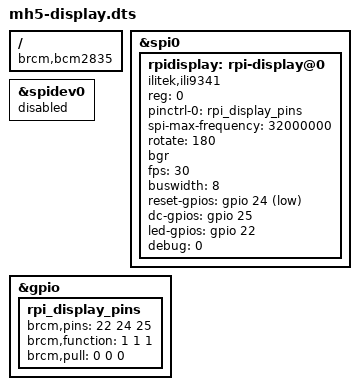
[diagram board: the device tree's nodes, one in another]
/*
 * Device Tree overlay for MH5 Display
 * based on rpi-display by Watterott
 *
 */

/dts-v1/;
/plugin/;

/ {
	compatible = "brcm,bcm2835";

	fragment@0 {
		target = <&spi0>;
		__overlay__ {
			status = "okay";
		};
	};

	fragment@1 {
		target = <&spidev0>;
		__overlay__ {
			status = "disabled";
		};
	};

	fragment@3 {
		target = <&gpio>;
		__overlay__ {
			rpi_display_pins: rpi_display_pins {
				brcm,pins = <22 24 25>;
				brcm,function = <1 1 1>; /* out out out out */
				brcm,pull = <0 0 0>; /* - - - - */
			};
		};
	};

	fragment@4 {
		target = <&spi0>;
		__overlay__ {
			/* needed to avoid dtc warning */
			#address-cells = <1>;
			#size-cells = <0>;

			rpidisplay: rpi-display@0{
				compatible = "ilitek,ili9341";
				reg = <0>;
				pinctrl-names = "default";
				pinctrl-0 = <&rpi_display_pins>;

				spi-max-frequency = <32000000>;
				rotate = <180>;
				bgr;
				fps = <30>;
				buswidth = <8>;
				reset-gpios = <&gpio 24 1>;
				dc-gpios = <&gpio 25 0>;
				led-gpios = <&gpio 22 0>;
				debug = <0>;
			};

		};
	};
	__overrides__ {
		speed =     <&rpidisplay>,"spi-max-frequency:0";
		rotate =    <&rpidisplay>,"rotate:0";
		fps =       <&rpidisplay>,"fps:0";
		debug =     <&rpidisplay>,"debug:0";
		backlight = <&rpidisplay>,"led-gpios:4",
		            <&rpi_display_pins>,"brcm,pins:0";
	};
};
